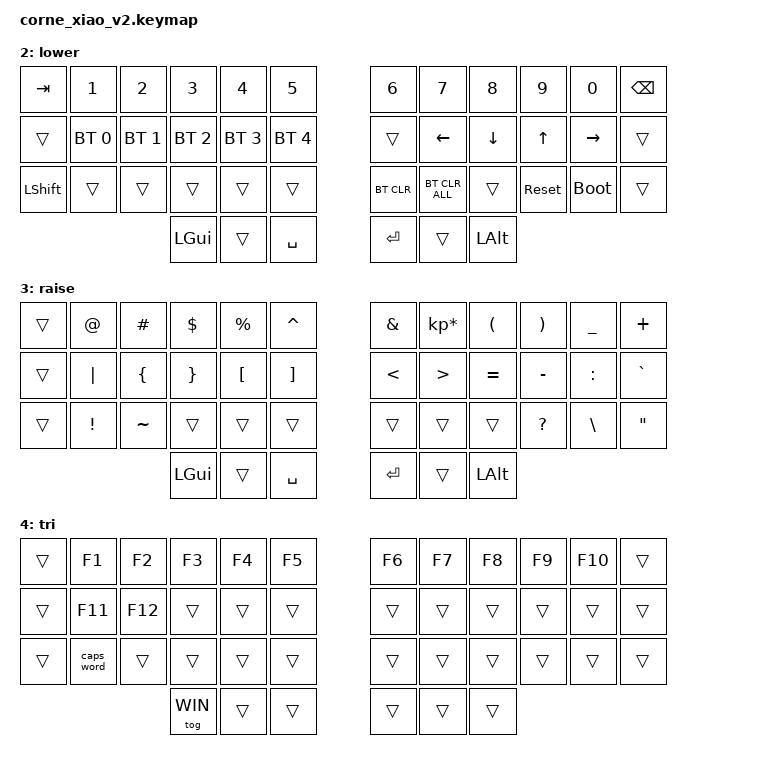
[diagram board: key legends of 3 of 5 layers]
#include <behaviors.dtsi>
#include <dt-bindings/zmk/keys.h>
#include <dt-bindings/zmk/bt.h>

// =========================================================================================
// 🧩 HOME ROW MODS
// =========================================================================================


// Mac/Linux-style Home Row Mods
#define HRML(k1, k2, k3, k4) &ht LSHIFT k1  &ht LALT k2  &ht LCTRL k3  &ht LGUI k4
#define HRMR(k1, k2, k3, k4) &ht RGUI k1    &ht RCTRL k2  &ht RALT k3  &ht RSHIFT k4

// Windows-style Home Row Mods (GUI before CTRL)
#define WHRML(k1, k2, k3, k4) &ht LSHIFT k1  &ht LALT k2  &ht LGUI k3  &ht LCTRL k4
#define WHRMR(k1, k2, k3, k4) &ht RCTRL k1   &ht RGUI k2  &ht RALT k3  &ht RSHIFT k4

// =========================================================================================
// 🗂️ LAYER INDICES
// =========================================================================================
#define MAC 0
#define WIN 1
#define LOW 2
#define RAI 3
#define TRI 4

/ {
    behaviors {
        ht: hold_tap {
            label = "hold_tap";
            compatible = "zmk,behavior-hold-tap";
            #binding-cells = <2>;
            flavor = "tap-preferred";
            tapping-term-ms = <220>;
            quick-tap-ms = <150>;
            global-quick-tap;
            bindings = <&kp>, <&kp>;
        };
    };

    conditional_layers {
        compatible = "zmk,conditional-layers";
        tri_layer {
            if-layers = <LOW RAI>;
            then-layer = <TRI>;
        };
    };

    combos {
        compatible = "zmk,combos";
        combo_studio_unlock {
            timeout-ms = <50>;
            key-positions = <0 1>;
            bindings = <&studio_unlock>;
        };
    };
};

 / {
    keymap {
        compatible = "zmk,keymap";

        // =========================================================================================
        // 🍎 MAC BASE LAYER
        // =========================================================================================
        mac_base {
            display-name = "mac_base";
            sensor-bindings = <&inc_dec_kp C_VOL_UP C_VOL_DN &inc_dec_kp PG_UP PG_DN>;

            //╭──────────┬──────────┬──────────┬───────────┬──────────┬──────────╮   ╭──────────┬──────────┬──────────┬──────────┬──────────┬──────────╮
            //│   TAB    │   Q      │   W      │   E       │   R      │   T      │   │   Y      │   U      │   I      │   O      │   P      │  BKSP    │
            //├──────────┼──────────┼──────────┼───────────┼──────────┼──────────┤   ├──────────┼──────────┼──────────┼──────────┼──────────┼──────────┤
            //│   CTRL   │   A      │   S      │   D       │   F      │   G      │   │   H      │   J      │   K      │   L      │   ;      │   '      │
            //├──────────┼──────────┼──────────┼───────────┼──────────┼──────────┤   ├──────────┼──────────┼──────────┼──────────┼──────────┼──────────┤
            //│   SHFT   │   Z      │   X      │   C       │   V      │   B      │   │   N      │   M      │   ,      │   .      │   /      │   ESC    │
            //╰──────────┴──────────┴──────────┴───────────┴──────────┴──────────╯   ╰──────────┴──────────┴──────────┴──────────┴──────────┴──────────╯
            //                                      │   GUI   │   LWR   │  SPACE │   │ ENTER  │  RAI   │  ALT   │
            //                                      ╰─────────┴─────────┴────────╯   ╰────────┴────────┴────────╯

            bindings = <
&kp TAB   &kp Q &kp W &kp E   &kp R &kp T                         &kp Y   &kp U   &kp I   &kp O   &kp P   &kp BSPC
&trans HRML(A, S, D, F) &kp G                               &kp H   HRMR(J, K, L, SEMI) &kp SQT
&kp LSHIFT &kp Z &kp X &kp C &kp V &kp B                        &kp N   &kp M &kp COMMA &kp DOT &kp FSLH &kp ESC
                        &kp LGUI &lt LWR TAB &kp SPACE             &kp RET &lt RAI RSHIFT &kp LALT
            >;
        };

        // =========================================================================================
        // 🪟 WINDOWS BASE LAYER
        // =========================================================================================
        win_base {
            display-name = "win_base";
            sensor-bindings = <&inc_dec_kp C_VOL_UP C_VOL_DN &inc_dec_kp PG_UP PG_DN>;

            //╭──────────┬──────────┬──────────┬───────────┬──────────┬──────────╮   ╭──────────┬──────────┬──────────┬──────────┬──────────┬──────────╮
            //│   TAB    │   Q      │   W      │   E       │   R      │   T      │   │   Y      │   U      │   I      │   O      │   P      │  BKSP    │
            //├──────────┼──────────┼──────────┼───────────┼──────────┼──────────┤   ├──────────┼──────────┼──────────┼──────────┼──────────┼──────────┤
            //│   CTRL   │   A      │   S      │   D       │   F      │   G      │   │   H      │   J      │   K      │   L      │   ;      │   '      │
            //├──────────┼──────────┼──────────┼───────────┼──────────┼──────────┤   ├──────────┼──────────┼──────────┼──────────┼──────────┼──────────┤
            //│   SHFT   │   Z      │   X      │   C       │   V      │   B      │   │   N      │   M      │   ,      │   .      │   /      │   ESC    │
            //╰──────────┴──────────┴──────────┴───────────┴──────────┴──────────╯   ╰──────────┴──────────┴──────────┴──────────┴──────────┴──────────╯
            //                                      │   GUI   │   LWR   │  SPACE │   │   ENTER  │   RAI  │  ALT   │
            //                                      ╰─────────┴─────────┴────────╯   ╰──────────┴────────┴────────╯

            bindings = <
&kp TAB   &kp Q &kp W &kp E   &kp R &kp T                         &kp Y   &kp U   &kp I   &kp O   &kp P   &kp BSPC
&kp LCTRL WHRML(A, S, D, F) &kp G                               &kp H   WHRMR(J, K, L, SEMI) &kp SQT
&kp LSHIFT &kp Z &kp X &kp C &kp V &kp B                        &kp N   &kp M &kp COMMA &kp DOT &kp FSLH &kp ESC
                       &kp LGUI &lt LWR TAB &kp SPACE             &kp RET &lt RAI RSHIFT &kp LALT
            >;
        };

        // =========================================================================================
        // ⬇️ LOWER LAYER
        // =========================================================================================
        lower {
            display-name = "lower";
            sensor-bindings = <&inc_dec_kp C_VOL_UP C_VOL_DN &inc_dec_kp PG_UP PG_DN>;

            //╭──────────┬──────────┬──────────┬───────────┬──────────┬──────────╮   ╭──────────┬──────────┬──────────┬──────────┬──────────┬──────────╮
            //│   TAB    │   1      │   2      │   3       │   4      │   5      │   │   6      │   7      │   8      │   9      │   0      │  BKSP    │
            //├──────────┼──────────┼──────────┼───────────┼──────────┼──────────┤   ├──────────┼──────────┼──────────┼──────────┼──────────┼──────────┤
            //│          │  BT1     │  BT2     │  BT3      │  BT4     │  BT5     │   │          │   LEFT   │   DOWN   │    UP    │  RIGHT   │          │         
            //├──────────┼──────────┼──────────┼───────────┼──────────┼──────────┤   ├──────────┼──────────┼──────────┼──────────┼──────────┼──────────┤
            //│   SHFT   │          │          │           │          │          │   │  BT_CLR  │BT_CLR_ALL│          │  RESET   │   BOOT   │          │
            //╰──────────┴──────────┴──────────┴───────────┴──────────┴──────────╯   ╰──────────┴──────────┴──────────┴──────────┴──────────┴──────────╯
            //                                      │   GUI   │         │  SPACE │   │  ENTER  │        │   ALT  │
            //                                      ╰─────────┴─────────┴────────╯   ╰─────────┴────────┴────────╯

            bindings = <
&kp TAB &kp N1 &kp N2 &kp N3 &kp N4 &kp N5                                &kp N6 &kp N7 &kp N8 &kp N9 &kp N0 &kp BSPC
&trans &bt BT_SEL 0 &bt BT_SEL 1 &bt BT_SEL 2 &bt BT_SEL 3 &bt BT_SEL 4   &trans &kp LEFT &kp DOWN &kp UP &kp RIGHT &trans
&kp LSHIFT &trans &trans &trans &trans &trans                             &bt BT_CLR &bt BT_CLR_ALL &trans &sys_reset &bootloader &trans
                        &kp LGUI &trans &kp SPACE                         &kp RET &trans &kp LALT
            >;
        };

        // =========================================================================================
        // ⬆️ RAISE LAYER
        // =========================================================================================
        raise {
            display-name = "raise";
            sensor-bindings = <&inc_dec_kp C_VOL_UP C_VOL_DN &inc_dec_kp PG_UP PG_DN>;

            //╭──────────┬──────────┬──────────┬───────────┬──────────┬──────────╮   ╭──────────┬──────────┬──────────┬──────────┬──────────┬──────────╮
            //│          │   @      │   #      │   $       │   %      │   ^      │   │   &      │   *      │   (      │   )      │   _      │   +      │
            //├──────────┼──────────┼──────────┼───────────┼──────────┼──────────┤   ├──────────┼──────────┼──────────┼──────────┼──────────┼──────────┤
            //│          │    |     │   {      │   }       │   [      │   ]      │   │   <      │   >      │   =      │   -      │    :     │   `      │
            //├──────────┼──────────┼──────────┼───────────┼──────────┼──────────┤   ├──────────┼──────────┼──────────┼──────────┼──────────┼──────────┤
            //│  (empty) │    !     │    ~     │           │          │          │   │          │          │          │    ?     │   \      │    "     │
            //╰──────────┴──────────┴──────────┴───────────┴──────────┴──────────╯   ╰──────────┴──────────┴──────────┴──────────┴──────────┴──────────╯
            //                                      │   GUI   │         │  SPACE │   │ ENTER  │        │   ALT   │
            //                                      ╰─────────┴─────────┴────────╯   ╰────────┴────────┴─────────╯

            bindings = <
&trans &kp AT &kp HASH &kp DLLR &kp PRCNT &kp CARET            &kp AMPS &kp KP_MULTIPLY &kp LPAR &kp RPAR &kp UNDER &kp PLUS
&trans &kp PIPE &kp LBRC &kp RBRC &kp LBKT &kp RBKT            &kp LT &kp GT &kp EQUAL &kp MINUS &kp COLON &kp GRAVE 
&trans &kp EXCL &kp TILDE &trans &trans &trans                 &trans &trans &trans &kp QMARK &kp BSLH &kp DQT
                        &kp LGUI &trans &kp SPACE              &kp RET &trans &kp LALT
            >;
        };

        // =========================================================================================
        // 🧱 TRI LAYER (LOW + RAI)
        // =========================================================================================
        tri {
            display-name = "tri";
            sensor-bindings = <&inc_dec_kp C_VOL_UP C_VOL_DN &inc_dec_kp PG_UP PG_DN>;

            //╭──────────┬──────────┬──────────┬───────────┬──────────┬──────────╮   ╭──────────┬──────────┬──────────┬──────────┬──────────┬──────────╮
            //│          │   F1     │   F2     │   F3      │   F4     │   F5     │   │   F6     │   F7     │   F8     │   F9     │   F10    │ NEXTSONG │  
            //├──────────┼──────────┼──────────┼───────────┼──────────┼──────────┤   ├──────────┼──────────┼──────────┼──────────┼──────────┼──────────┤
            //│ (empty)  │   F11    │   F12    │           │          │          │   │          │DEC BRIGHT│INC BRIGHT│ WINDOWS  │          │PAUSEMUSIC│
            //├──────────┼──────────┼──────────┼───────────┼──────────┼──────────┤   ├──────────┼──────────┼──────────┼──────────┼──────────┼──────────┤
            //│ (empty)  │Caps Word │          │           │          │          │   │          │ VOL DOWN │  VOL UP  │ VOL MUTE │ZMK STUDIO│ PREVSONG │
            //╰──────────┴──────────┴──────────┴───────────┴──────────┴──────────╯   ╰──────────┴──────────┴──────────┴──────────┴──────────┴──────────╯
                        //                          │ WIN TOG │         │        │   │ (trans) │ (trans)│ (trans)│
                        //                          ╰─────────┴─────────┴────────╯   ╰─────────┴────────┴────────╯

//             bindings = <
// &trans &kp F1 &kp F2 &kp F3 &kp F4 &kp F5                        &kp F6 &kp F7 &kp F8 &kp F9 &kp F10 &kp C_NEXT
// &trans &kp F11 &kp F12 &trans &trans &trans                      &trans &kp C_BRI_DEC &kp C_BRI_UP &tog WIN &trans &kp C_PP
// &trans &caps_word &trans &trans &trans &trans                    &trans &kp C_VOL_DN &kp C_VOL_UP &kp C_MUTE &studio_unlock &kp C_PREV
//                         &tog WIN &trans &trans                   &trans &trans &trans
//             >;
            bindings = <
&trans &kp F1 &kp F2 &kp F3 &kp F4 &kp F5                        &kp F6 &kp F7 &kp F8 &kp F9 &kp F10 &trans
&trans &kp F11 &kp F12 &trans &trans &trans                      &trans &trans &trans &trans &trans &trans 
&trans &caps_word &trans &trans &trans &trans                    &trans &trans &trans &trans &trans &trans 
                        &tog WIN &trans &trans                   &trans &trans &trans
            >;
        };

        extra1 {
            display-name = "extra1";
            status = "reserved";
        };

        extra2 {
            display-name = "extra2";
            status = "reserved";
        };
    };
};
